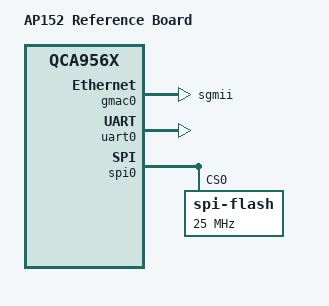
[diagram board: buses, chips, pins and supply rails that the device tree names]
// SPDX-License-Identifier: GPL-2.0+
/*
 * Copyright (C) 2018 Rosy Song <rosysong@rosinson.com>
 */

/dts-v1/;
#include "qca956x.dtsi"

/ {
	model = "AP152 Reference Board";
	compatible = "qca,ap152", "qca,qca956x";

	aliases {
		spi0 = &spi0;
		serial0 = &uart0;
	};

	chosen {
		stdout-path = "serial0:115200n8";
	};
};

&gmac0 {
	phy-mode = "sgmii";
	status = "okay";
};

&xtal {
	clock-frequency = <25000000>;
};

&uart0 {
	clock-frequency = <25000000>;
	status = "okay";
};

&spi0 {
	spi-max-frequency = <25000000>;
	status = "okay";
	spi-flash@0 {
		#address-cells = <1>;
		#size-cells = <1>;
		compatible = "spi-flash";
		memory-map = <0x9f000000 0x01000000>;
		spi-max-frequency = <25000000>;
		reg = <0>;
	};
};
